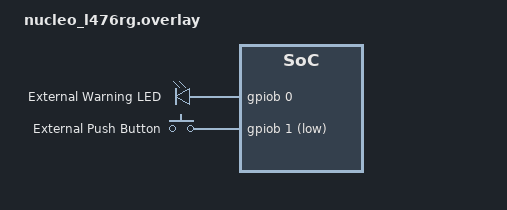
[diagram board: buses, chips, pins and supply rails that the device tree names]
/ {
    aliases {
        ext-led = &ext_led_node;
        ext-button = &ext_btn_node;
    };

    external_io {
        compatible = "gpio-leds";
        ext_led_node: ext_led_0 {
            gpios = <&gpiob 0 GPIO_ACTIVE_HIGH>;
            label = "External Warning LED";
        };
    };

    external_keys {
        compatible = "gpio-keys";
        ext_btn_node: ext_btn_0 {
            gpios = <&gpiob 1 (GPIO_PULL_UP | GPIO_ACTIVE_LOW)>;
            label = "External Push Button";
        };
    };
};
